# hercules_mdio_spec_1.2.0 register map
Vendor: Texas Instruments
Peripheral module from a debugger description file (folder hercules).
Registers are 32-bit, access not given, reset 0x0 unless marked. A register's access mark holds for its fields unless they carry their own. Offsets are as the file gives them; lines under a group give offsets from that group; [hi:lo] are bit positions; {n}, {i} and the like mark numbered series; 'fields as' and 'values as' point back to an identical list; <NAME> marks a mode.

## MDIO — VBUS MII Management Interface
0x00 REV ro reset 0x70104 — MDIO Version Register
  [31:0] REGVAL
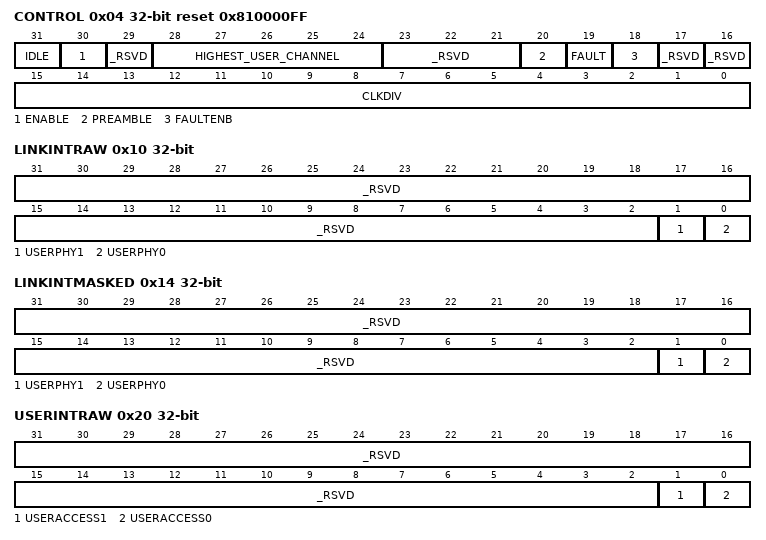
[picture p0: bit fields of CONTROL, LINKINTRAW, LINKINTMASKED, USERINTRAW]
0x04 CONTROL reset 0x810000FF — MDIO Control Register
  [31] IDLE ro — Sets MDIO state machine to idle
    0=NO; 1=YES
  [30] ENABLE rw — Enable state machine; must be last bit written to register
    0=NO; 1=YES
  [29] _RSVD — (access N)
  [28:24] HIGHEST_USER_CHANNEL ro — Highest user access channel that is available in module.
  [23:21] _RSVD — (access N)
  [20] PREAMBLE rw — Preamble Disable
    0=ENABLE; 1=DISABLE
  [19] FAULT rw — Fault indicator; Write to clear
  [18] FAULTENB rw — Fault detect enable
    0=DISABLE; 1=ENABLE
  [17] _RSVD — Interrupt test enable for userint and linkint (access N)
  [16] _RSVD — (access N)
  [15:0] CLKDIV rw — Clock divider for MDCLK. MDCLK = CLK/(CLKDIV+1)
    0=DISABLE
0x08 ALIVE rw — MDIO Alive Register
  [31:0] REGVAL — MDIO ALIVE; Gives presence indication of PHY; write to clear
0x0C LINK ro — MDIO Link Register
  [31:0] REGVAL — MDIO Link State; Gives presence indication of PHY link
0x10 LINKINTRAW — MDIO Link Interrupt Raw Register
  [31:2] _RSVD — (access N)
  [1] USERPHY1 rw — MDIO Link change event, raw value; write to clear.
  [0] USERPHY0 rw — MDIO Link change event, raw value; write to clear.
0x14 LINKINTMASKED — MDIO Link Interrupt Masked Register
  [31:2] _RSVD — (access N)
  [1] USERPHY1 rw — MDIO Link change event, masked value; write to clear.
  [0] USERPHY0 rw — MDIO Link change event, masked value; write to clear.
0x20 USERINTRAW — MDIO User Interrupt Raw Register
  [31:2] _RSVD — (access N)
  [1] USERACCESS1 rw — MDIO user command complete event, raw value; write to clear.
  [0] USERACCESS0 rw — MDIO user command complete event, raw value; write to clear.
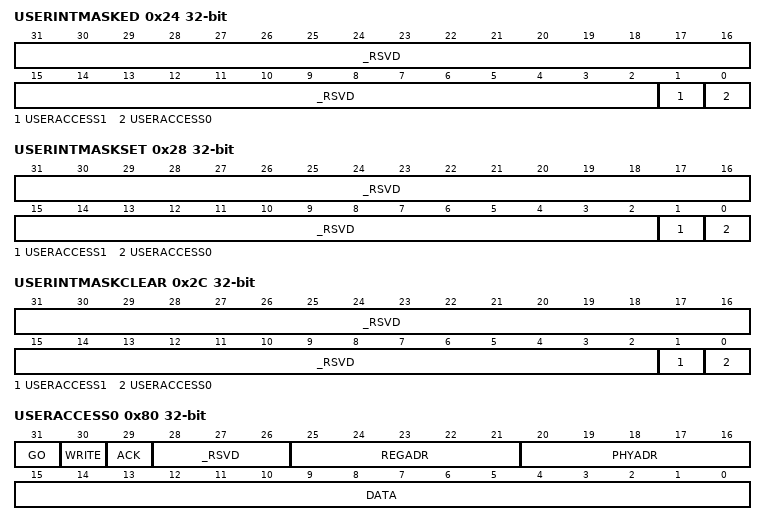
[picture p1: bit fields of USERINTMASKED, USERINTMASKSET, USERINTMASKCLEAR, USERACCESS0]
0x24 USERINTMASKED — MDIO User Interrupt Masked Register
  [31:2] _RSVD — (access N)
  [1] USERACCESS1 rw — MDIO user command complete event, masked value; write to clear.
  [0] USERACCESS0 rw — MDIO user command complete event, masked value; write to clear.
0x28 USERINTMASKSET — MDIO User Interrupt Mask Set Register
  [31:2] _RSVD — (access N)
  [1] USERACCESS1 rw — MDIO User interrupt mask set; write to set
  [0] USERACCESS0 rw — MDIO User interrupt mask set; write to set
0x2C USERINTMASKCLEAR — MDIO User Interrupt Mask Clear Register
  fields as USERINTMASKSET
0x80 USERACCESS0 — MDIO User Access Register 0
  [31] GO rw — Writing a 1 causes MDIO state machine to start an MDIO access sequence
  [30] WRITE rw — Write Enable
  [29] ACK rw — PHY ACK of read transaction
  [28:26] _RSVD — (access N)
  [25:21] REGADR rw — Register Address. Specifies PHY register to be accessed for transaction
  [20:16] PHYADR rw — PHY Address. Specifies PHY to be accessed for transaction
  [15:0] DATA rw — User Data. Data to be read or written to PHY register
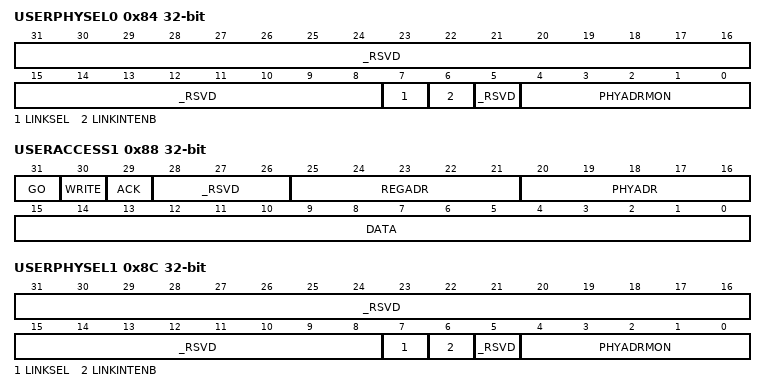
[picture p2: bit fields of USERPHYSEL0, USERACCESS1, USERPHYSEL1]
0x84 USERPHYSEL0 — MDIO User PHY Select REG0
  [31:8] _RSVD — (access N)
  [7] LINKSEL rw — Link status determination; 1 to determine link status using MLINK pin.
  [6] LINKINTENB rw — Link change interrupt enable.
  [5] _RSVD — (access N)
  [4:0] PHYADRMON rw — Register Address. Specifies PHY register to be accessed for transaction
0x88 USERACCESS1 — MDIO User Access Register 1
  fields as USERACCESS0
0x8C USERPHYSEL1 — MDIO User PHY Select REG1
  fields as USERPHYSEL0
